# STM32F40x register map
File version: 1.5
Registers are 32-bit, read-write, reset 0x0 unless marked. A register's access mark holds for its fields unless they carry their own. Offsets are from the block's base; [hi:lo] are bit positions; {n}, {i} and the like mark numbered series.

## TIM2（定时器2(通用定时器)） — 通用定时器：计数/比较/PWM/输入捕获 | General purpose timers
Base 0x40000000
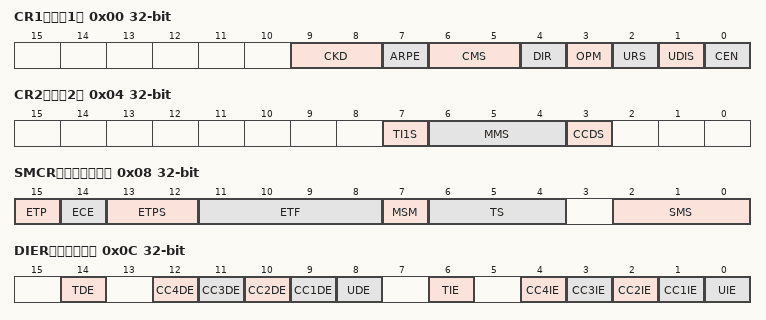
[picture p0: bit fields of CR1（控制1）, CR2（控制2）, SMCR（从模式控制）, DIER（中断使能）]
0x00 CR1（控制1） — 控制1：计数器使能/方向/对齐/分频 | control register 1
  [9:8] CKD — Clock division
  [7] ARPE — Auto-reload preload enable
  [6:5] CMS — Center-aligned mode selection
  [4] DIR — Direction
  [3] OPM — One-pulse mode
  [2] URS — Update request source
  [1] UDIS — Update disable
  [0] CEN — Counter enable
0x04 CR2（控制2） — 控制2：主从模式/输出空闲状态 | control register 2
  [7] TI1S — TI1 selection
  [6:4] MMS — Master mode selection
  [3] CCDS — Capture/compare DMA selection
0x08 SMCR（从模式控制） — 从模式控制：触发/门控/外部时钟选择 | slave mode control register
  [15] ETP — External trigger polarity
  [14] ECE — External clock enable
  [13:12] ETPS — External trigger prescaler
  [11:8] ETF — External trigger filter
  [7] MSM — Master/Slave mode
  [6:4] TS — Trigger selection
  [2:0] SMS — Slave mode selection
0x0C DIER（中断使能） — DMA/中断使能：更新/捕获/触发 | DMA/Interrupt enable register
  [14] TDE — Trigger DMA request enable
  [n+8] CC{n}DE (n=1..4) — Capture/Compare {n} DMA request enable
  [8] UDE — Update DMA request enable
  [6] TIE — Trigger interrupt enable
  [n] CC{n}IE (n=1..4) — Capture/Compare {n} interrupt enable
  [0] UIE — Update interrupt enable
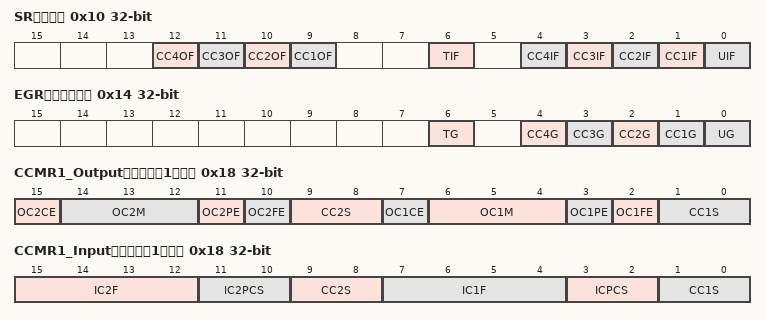
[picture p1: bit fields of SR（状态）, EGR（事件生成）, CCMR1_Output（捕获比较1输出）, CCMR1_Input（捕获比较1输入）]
0x10 SR（状态） — 状态：更新/捕获/触发 等中断标志 | status register
  [12] CC4OF — Capture/Compare 4 overcapture flag
  [11] CC3OF — Capture/Compare 3 overcapture flag
  [10] CC2OF — Capture/compare 2 overcapture flag
  [9] CC1OF — Capture/Compare 1 overcapture flag
  [6] TIF — Trigger interrupt flag
  [4] CC4IF — Capture/Compare 4 interrupt flag
  [3] CC3IF — Capture/Compare 3 interrupt flag
  [2] CC2IF — Capture/Compare 2 interrupt flag
  [1] CC1IF — Capture/compare 1 interrupt flag
  [0] UIF — Update interrupt flag
0x14 EGR（事件生成） wo — 事件生成：软件触发更新/捕获事件 | event generation register
  [6] TG — Trigger generation
  [n] CC{n}G (n=1..4) — Capture/compare {n} generation
  [0] UG — Update generation
0x18 CCMR1_Output（捕获比较1输出） — 通道1/2 输出比较模式 | capture/compare mode register 1 (output mode)
  [15] OC2CE, [14:12] OC2M, [11] OC2PE, [10] OC2FE, [9:8] CC2S, [7] OC1CE, [6:4] OC1M, [3] OC1PE, [2] OC1FE, [1:0] CC1S
0x18 CCMR1_Input（捕获比较1输入） (alternate view of CCMR1_Output) — 通道1/2 输入捕获模式 | capture/compare mode register 1 (input mode)
  [15:12] IC2F — Input capture 2 filter
  [11:10] IC2PCS — Input capture 2 prescaler
  [9:8] CC2S — Capture/Compare 2 selection
  [7:4] IC1F — Input capture 1 filter
  [3:2] ICPCS — Input capture 1 prescaler
  [1:0] CC1S — Capture/Compare 1 selection
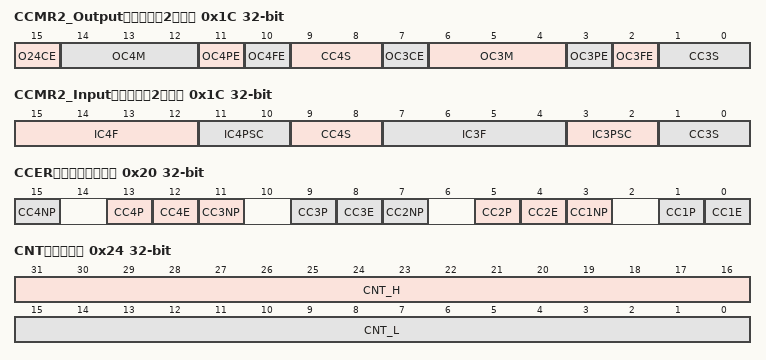
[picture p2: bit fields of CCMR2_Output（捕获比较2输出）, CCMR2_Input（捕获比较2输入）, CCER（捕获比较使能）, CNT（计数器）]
0x1C CCMR2_Output（捕获比较2输出） — 通道3/4 输出比较模式 | capture/compare mode register 2 (output mode)
  [15] O24CE, [14:12] OC4M, [11] OC4PE, [10] OC4FE, [9:8] CC4S, [7] OC3CE, [6:4] OC3M, [3] OC3PE, [2] OC3FE, [1:0] CC3S
0x1C CCMR2_Input（捕获比较2输入） (alternate view of CCMR2_Output) — 通道3/4 输入捕获模式 | capture/compare mode register 2 (input mode)
  [15:12] IC4F — Input capture 4 filter
  [11:10] IC4PSC — Input capture 4 prescaler
  [9:8] CC4S — Capture/Compare 4 selection
  [7:4] IC3F — Input capture 3 filter
  [3:2] IC3PSC — Input capture 3 prescaler
  [1:0] CC3S — Capture/compare 3 selection
0x20 CCER（捕获比较使能） — 各通道 使能/极性/方向 | capture/compare enable register
  [4n-1] CC{n}NP (n=1..4) — Capture/Compare {n} output Polarity
  [13] CC4P — Capture/Compare 3 output Polarity
  [4n-4] CC{n}E (n=1..4) — Capture/Compare {n} output enable
  [9] CC3P — Capture/Compare 3 output Polarity
  [5] CC2P — Capture/Compare 2 output Polarity
  [1] CC1P — Capture/Compare 1 output Polarity
0x24 CNT（计数器） — 当前计数值 | counter
  [31:16] CNT_H — High counter value
  [15:0] CNT_L — Low counter value
0x28 PSC（预分频） — 计数器时钟预分频 | prescaler
  [15:0] PSC — Prescaler value
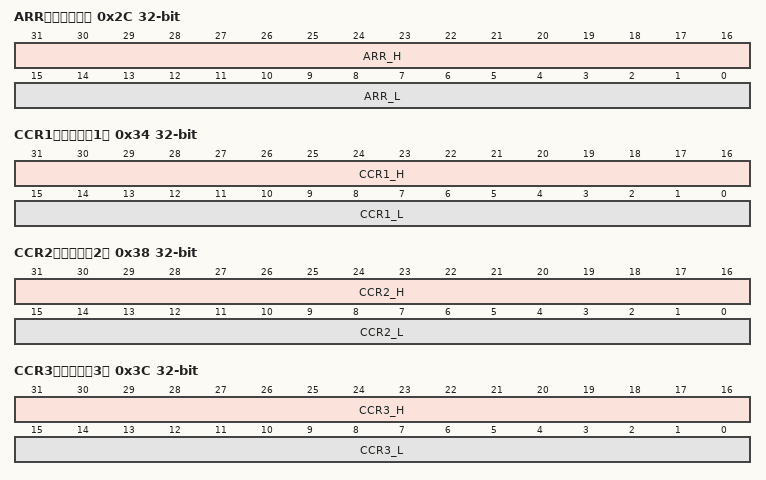
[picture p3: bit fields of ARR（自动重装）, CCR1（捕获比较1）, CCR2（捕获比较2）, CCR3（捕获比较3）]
0x2C ARR（自动重装） — 自动重装载值（周期） | auto-reload register
  [31:16] ARR_H — High Auto-reload value
  [15:0] ARR_L — Low Auto-reload value
0x34 CCR1（捕获比较1） — 通道1 比较值/捕获值 | capture/compare register 1
  [31:16] CCR1_H — High Capture/Compare 1 value
  [15:0] CCR1_L — Low Capture/Compare 1 value
0x38 CCR2（捕获比较2） — 通道2 比较值/捕获值 | capture/compare register 2
  [31:16] CCR2_H — High Capture/Compare 2 value
  [15:0] CCR2_L — Low Capture/Compare 2 value
0x3C CCR3（捕获比较3） — 通道3 比较值/捕获值 | capture/compare register 3
  [31:16] CCR3_H — High Capture/Compare value
  [15:0] CCR3_L — Low Capture/Compare value
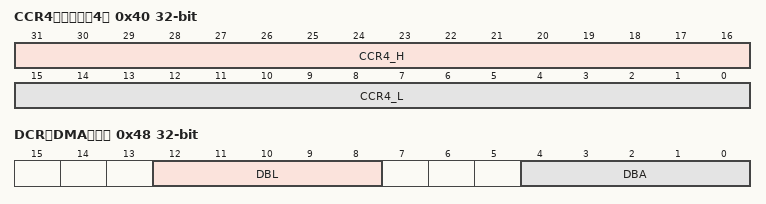
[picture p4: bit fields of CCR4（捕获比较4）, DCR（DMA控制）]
0x40 CCR4（捕获比较4） — 通道4 比较值/捕获值 | capture/compare register 4
  [31:16] CCR4_H — High Capture/Compare value
  [15:0] CCR4_L — Low Capture/Compare value
0x48 DCR（DMA控制） — DMA 突发访问配置 | DMA control register
  [12:8] DBL — DMA burst length
  [4:0] DBA — DMA base address
0x4C DMAR（DMA地址） — DMA 连续访问数据 | DMA address for full transfer
  [15:0] DMAB — DMA register for burst accesses
0x50 OR（复用） — 定时器复用功能 | TIM5 option register
  [11:10] ITR1_RMP — Timer Input 4 remap

## TIM3（定时器3(通用定时器)） — 通用定时器：计数/比较/PWM/输入捕获 | General purpose timers
Base 0x40000400
Same registers: TIM4（定时器4(通用定时器)） 0x40000800
Registers as TIM2（定时器2(通用定时器)）, without OR（复用）.

## TIM5（定时器5(通用定时器)） — 通用定时器：计数/比较/PWM/输入捕获 | General-purpose-timers
Base 0x40000C00
Registers as TIM2（定时器2(通用定时器)）; these are added or differ:
0x50 OR（复用） — 定时器复用功能 | TIM5 option register
  [7:6] IT4_RMP — Timer Input 4 remap
